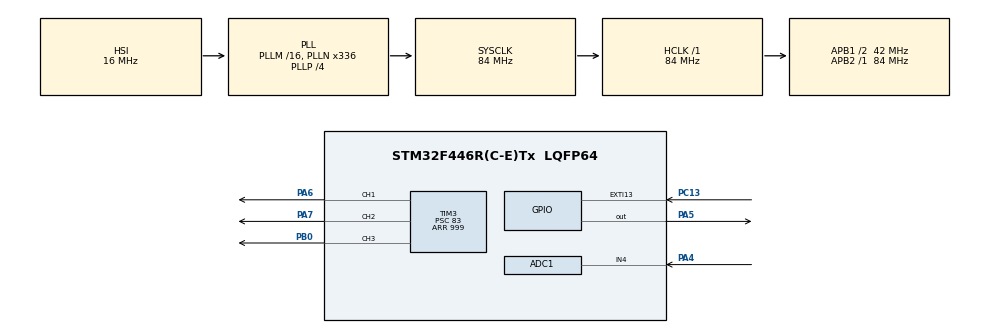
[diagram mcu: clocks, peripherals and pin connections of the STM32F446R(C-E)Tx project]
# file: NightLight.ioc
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ADC1.Channel-0\#ChannelRegularConversion=ADC_CHANNEL_4
ADC1.ExternalTrigConv=ADC_EXTERNALTRIGCONV_T2_TRGO
ADC1.NbrOfConversion=1
ADC1.NbrOfConversionFlag=1
ADC1.Rank-0\#ChannelRegularConversion=1
ADC1.SamplingTime-0\#ChannelRegularConversion=ADC_SAMPLETIME_84CYCLES
ADC1.master=1
Mcu.Family=STM32F4
Mcu.Name=STM32F446R(C-E)Tx
Mcu.Package=LQFP64
NUCLEO-F446RE.BUTTON=1
NUCLEO-F446RE.LD1=true
NVIC.ADC_IRQn=true\:0\:0\:false\:false\:true\:true\:true\:true
NVIC.EXTI15_10_IRQn=true\:0\:0\:false\:false\:true\:false\:true\:true
NVIC.PriorityGroup=NVIC_PRIORITYGROUP_0
PA13.GPIO_Label=TMS
PA13.Signal=SYS_JTMS-SWDIO
PA14.GPIO_Label=TCK
PA14.Signal=SYS_JTCK-SWCLK
PA2.GPIO_Label=USART_TX
PA2.Signal=USART2_TX
PA3.GPIO_Label=USART_RX
PA3.Signal=USART2_RX
PA4.Signal=SharedAnalog_PA4
PA5.Signal=GPIO_Output
PA6.Signal=S_TIM3_CH1
PA7.Signal=S_TIM3_CH2
PB0.Signal=S_TIM3_CH3
PB3.GPIO_Label=SWO
PB3.Signal=SYS_JTDO-SWO
PC13.Signal=GPXTI13
PC14-OSC32_IN.Signal=RCC_OSC32_IN
PC15-OSC32_OUT.Signal=RCC_OSC32_OUT
PH0-OSC_IN.Signal=RCC_OSC_IN
PH1-OSC_OUT.Signal=RCC_OSC_OUT
ProjectManager.HeapSize=0x200
ProjectManager.StackSize=0x400
ProjectManager.TargetToolchain=STM32CubeIDE
RCC.AHBFreq_Value=84000000
RCC.APB1CLKDivider=RCC_HCLK_DIV2
RCC.APB1Freq_Value=42000000
RCC.APB1TimFreq_Value=84000000
RCC.APB2Freq_Value=84000000
RCC.APB2TimFreq_Value=84000000
RCC.CortexFreq_Value=84000000
RCC.FLatency-AdvancedSettings=FLASH_LATENCY_2
RCC.HCLKFreq_Value=84000000
RCC.HSE_VALUE=8000000
RCC.HSI_VALUE=16000000
RCC.LSE_VALUE=32768
RCC.PLLN=336
RCC.PLLP=RCC_PLLP_DIV4
RCC.SYSCLKFreq_VALUE=84000000
RCC.SYSCLKSource=RCC_SYSCLKSOURCE_PLLCLK
RCC.USBFreq_Value=168000000
RCC.VCOOutputFreq_Value=336000000
SH.S_TIM3_CH1.0=TIM3_CH1,PWM Generation1 CH1
SH.S_TIM3_CH2.0=TIM3_CH2,PWM Generation2 CH2
SH.S_TIM3_CH3.0=TIM3_CH3,PWM Generation3 CH3
SH.SharedAnalog_PA4.0=ADC1_IN4,IN4
SH.SharedAnalog_PA4.1=DAC_OUT1,DAC_OUT1
TIM2.Period=99
TIM2.Prescaler=8399
TIM2.TIM_MasterOutputTrigger=TIM_TRGO_UPDATE
TIM3.Channel-PWM\ Generation1\ CH1=TIM_CHANNEL_1
TIM3.Channel-PWM\ Generation2\ CH2=TIM_CHANNEL_2
TIM3.Channel-PWM\ Generation3\ CH3=TIM_CHANNEL_3
TIM3.Period=999
TIM3.Prescaler=83
VP_NUCLEO-F446RE_VS_BSP_COMMON.Mode=COMMON
VP_TIM2_VS_ClockSourceINT.Mode=Internal
board=NUCLEO-F446RE

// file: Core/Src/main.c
/* USER CODE BEGIN Header */
/**
  ******************************************************************************
  * @file           : main.c
  * @brief          : Main program body
  ******************************************************************************
  * @attention
  *
  * Copyright (c) 2026 STMicroelectronics.
  * All rights reserved.
  *
  * This software is licensed under terms that can be found in the LICENSE file
  * in the root directory of this software component.
  * If no LICENSE file comes with this software, it is provided AS-IS.
  *
  ******************************************************************************
  */
/* USER CODE END Header */
#include "main.h"

ADC_HandleTypeDef hadc1;

DAC_HandleTypeDef hdac;

TIM_HandleTypeDef htim2;
TIM_HandleTypeDef htim3;

#define ENABLE_DAC_SELFTEST 0 //config, if 1, we disconnect PA4 from the Photoresistor voltage divider

static volatile uint32_t dac_test_value = 0;

#define ADC_MAX  4095U
#define PWM_MAX  999U

/* USER CODE BEGIN PV */
volatile uint32_t debug_adc = 0;
volatile uint32_t debug_brightness = 0;

/* USER CODE END PV */

void SystemClock_Config(void);
static void MX_GPIO_Init(void);
static void MX_ADC1_Init(void);
static void MX_DAC_Init(void);
static void MX_TIM2_Init(void);
static void MX_TIM3_Init(void);

static void update_PWM(uint32_t adc_value)
{
    uint32_t darkness = ADC_MAX - adc_value;

    uint32_t red = 0;
    uint32_t green = 0;
    uint32_t blue = 0;

    if (darkness < 1365U)
    {
        // First third: red ramps
        red = (darkness * PWM_MAX) / 1365U;
    }
    else if (darkness < 2730U)
    {
        // Second third: red on, green ramps
        red = PWM_MAX;
        green = ((darkness - 1365U) * PWM_MAX) / 1365U;

    }
    else
    {
        // Final third: rg on, blue ramps
        red = PWM_MAX;
        green = PWM_MAX;
        blue = ((darkness - 2730U) * PWM_MAX) / 1365U;
	}

    //Scaling to smoother visual transition
    red = red * red / PWM_MAX;
    green = green * green / PWM_MAX;
    blue = blue * blue / (PWM_MAX);

    __HAL_TIM_SET_COMPARE(&htim3, TIM_CHANNEL_1, red);
    __HAL_TIM_SET_COMPARE(&htim3, TIM_CHANNEL_2, green);
    __HAL_TIM_SET_COMPARE(&htim3, TIM_CHANNEL_3, blue);
}

void HAL_ADC_ConvCpltCallback(ADC_HandleTypeDef *hadc)
{
    if (hadc->Instance == ADC1)
    {

        debug_adc = HAL_ADC_GetValue(hadc);

		update_PWM(debug_adc);

		#if ENABLE_DAC_SELFTEST
				dac_test_value += 1;

				if (dac_test_value > 4095)
				{
					dac_test_value = 0;
				}

				HAL_DAC_SetValue(
					&hdac,
					DAC_CHANNEL_1,
					DAC_ALIGN_12B_R,
					dac_test_value
				);
		#endif
    }
}

int main(void)
{
	HAL_Init();
	SystemClock_Config();
	MX_GPIO_Init();
	MX_ADC1_Init();
	MX_DAC_Init();
	MX_TIM2_Init();
	MX_TIM3_Init();

	#if ENABLE_DAC_SELFTEST
		HAL_DAC_Start(&hdac, DAC_CHANNEL_1);
		HAL_DAC_SetValue(&hdac, DAC_CHANNEL_1, DAC_ALIGN_12B_R, dac_test_value);
	#endif

	HAL_TIM_PWM_Start(&htim3, TIM_CHANNEL_1);
	HAL_TIM_PWM_Start(&htim3, TIM_CHANNEL_2);
	HAL_TIM_PWM_Start(&htim3, TIM_CHANNEL_3);

	HAL_ADC_Start_IT(&hadc1);
	HAL_TIM_Base_Start(&htim2);

//  /* Initialize leds */
//  BSP_LED_Init(LED2);
//
//  /* Initialize USER push-button, will be used to trigger an interrupt each time it's pressed.*/
//  BSP_PB_Init(BUTTON_USER, BUTTON_MODE_EXTI);

  /* Infinite loop */
  /* USER CODE BEGIN WHILE */
  while (1)
  {
	  __WFI();
  }
}

void SystemClock_Config(void)
{
  RCC_OscInitTypeDef RCC_OscInitStruct = {0};
  RCC_ClkInitTypeDef RCC_ClkInitStruct = {0};

  /** Configure the main internal regulator output voltage
  */
  __HAL_RCC_PWR_CLK_ENABLE();
  __HAL_PWR_VOLTAGESCALING_CONFIG(PWR_REGULATOR_VOLTAGE_SCALE3);

  /** Initializes the RCC Oscillators according to the specified parameters
  * in the RCC_OscInitTypeDef structure.
  */
  RCC_OscInitStruct.OscillatorType = RCC_OSCILLATORTYPE_HSI;
  RCC_OscInitStruct.HSIState = RCC_HSI_ON;
  RCC_OscInitStruct.HSICalibrationValue = RCC_HSICALIBRATION_DEFAULT;
  RCC_OscInitStruct.PLL.PLLState = RCC_PLL_ON;
  RCC_OscInitStruct.PLL.PLLSource = RCC_PLLSOURCE_HSI;
  RCC_OscInitStruct.PLL.PLLM = 16;
  RCC_OscInitStruct.PLL.PLLN = 336;
  RCC_OscInitStruct.PLL.PLLP = RCC_PLLP_DIV4;
  RCC_OscInitStruct.PLL.PLLQ = 2;
  RCC_OscInitStruct.PLL.PLLR = 2;
  if (HAL_RCC_OscConfig(&RCC_OscInitStruct) != HAL_OK)
  {
    Error_Handler();
  }

  /** Initializes the CPU, AHB and APB buses clocks
  */
  RCC_ClkInitStruct.ClockType = RCC_CLOCKTYPE_HCLK|RCC_CLOCKTYPE_SYSCLK
                              |RCC_CLOCKTYPE_PCLK1|RCC_CLOCKTYPE_PCLK2;
  RCC_ClkInitStruct.SYSCLKSource = RCC_SYSCLKSOURCE_PLLCLK;
  RCC_ClkInitStruct.AHBCLKDivider = RCC_SYSCLK_DIV1;
  RCC_ClkInitStruct.APB1CLKDivider = RCC_HCLK_DIV2;
  RCC_ClkInitStruct.APB2CLKDivider = RCC_HCLK_DIV1;

  if (HAL_RCC_ClockConfig(&RCC_ClkInitStruct, FLASH_LATENCY_2) != HAL_OK)
  {
    Error_Handler();
  }
}

static void MX_ADC1_Init(void)
{

  ADC_ChannelConfTypeDef sConfig = {0};

  /** Configure the global features of the ADC (Clock, Resolution, Data Alignment and number of conversion)
  */
  hadc1.Instance = ADC1;
  hadc1.Init.ClockPrescaler = ADC_CLOCK_SYNC_PCLK_DIV4;
  hadc1.Init.Resolution = ADC_RESOLUTION_12B;
  hadc1.Init.ScanConvMode = DISABLE;
  hadc1.Init.ContinuousConvMode = DISABLE;
  hadc1.Init.DiscontinuousConvMode = DISABLE;
  hadc1.Init.ExternalTrigConvEdge = ADC_EXTERNALTRIGCONVEDGE_RISING;
  hadc1.Init.ExternalTrigConv = ADC_EXTERNALTRIGCONV_T2_TRGO;
  hadc1.Init.DataAlign = ADC_DATAALIGN_RIGHT;
  hadc1.Init.NbrOfConversion = 1;
  hadc1.Init.DMAContinuousRequests = DISABLE;
  hadc1.Init.EOCSelection = ADC_EOC_SINGLE_CONV;
  if (HAL_ADC_Init(&hadc1) != HAL_OK)
  {
    Error_Handler();
  }

  /** Configure for the selected ADC regular channel its corresponding rank in the sequencer and its sample time.
  */
  sConfig.Channel = ADC_CHANNEL_4;
  sConfig.Rank = 1;
  sConfig.SamplingTime = ADC_SAMPLETIME_84CYCLES;
  if (HAL_ADC_ConfigChannel(&hadc1, &sConfig) != HAL_OK)
  {
    Error_Handler();
  }

}

static void MX_DAC_Init(void)
{

  DAC_ChannelConfTypeDef sConfig = {0};

  /** DAC Initialization
  */
  hdac.Instance = DAC;
  if (HAL_DAC_Init(&hdac) != HAL_OK)
  {
    Error_Handler();
  }

  /** DAC channel OUT1 config
  */
  sConfig.DAC_Trigger = DAC_TRIGGER_NONE;
  sConfig.DAC_OutputBuffer = DAC_OUTPUTBUFFER_ENABLE;
  if (HAL_DAC_ConfigChannel(&hdac, &sConfig, DAC_CHANNEL_1) != HAL_OK)
  {
    Error_Handler();
  }

}

static void MX_TIM2_Init(void)
{

  TIM_ClockConfigTypeDef sClockSourceConfig = {0};
  TIM_MasterConfigTypeDef sMasterConfig = {0};

  htim2.Instance = TIM2;
  htim2.Init.Prescaler = 8399;
  htim2.Init.CounterMode = TIM_COUNTERMODE_UP;
  htim2.Init.Period = 99;
  htim2.Init.ClockDivision = TIM_CLOCKDIVISION_DIV1;
  htim2.Init.AutoReloadPreload = TIM_AUTORELOAD_PRELOAD_DISABLE;
  if (HAL_TIM_Base_Init(&htim2) != HAL_OK)
  {
    Error_Handler();
  }
  sClockSourceConfig.ClockSource = TIM_CLOCKSOURCE_INTERNAL;
  if (HAL_TIM_ConfigClockSource(&htim2, &sClockSourceConfig) != HAL_OK)
  {
    Error_Handler();
  }
  sMasterConfig.MasterOutputTrigger = TIM_TRGO_UPDATE;
  sMasterConfig.MasterSlaveMode = TIM_MASTERSLAVEMODE_DISABLE;
  if (HAL_TIMEx_MasterConfigSynchronization(&htim2, &sMasterConfig) != HAL_OK)
  {
    Error_Handler();
  }

}

static void MX_TIM3_Init(void)
{

  TIM_MasterConfigTypeDef sMasterConfig = {0};
  TIM_OC_InitTypeDef sConfigOC = {0};

  htim3.Instance = TIM3;
  htim3.Init.Prescaler = 83;
  htim3.Init.CounterMode = TIM_COUNTERMODE_UP;
  htim3.Init.Period = 999;
  htim3.Init.ClockDivision = TIM_CLOCKDIVISION_DIV1;
  htim3.Init.AutoReloadPreload = TIM_AUTORELOAD_PRELOAD_DISABLE;
  if (HAL_TIM_PWM_Init(&htim3) != HAL_OK)
  {
    Error_Handler();
  }
  sMasterConfig.MasterOutputTrigger = TIM_TRGO_RESET;
  sMasterConfig.MasterSlaveMode = TIM_MASTERSLAVEMODE_DISABLE;
  if (HAL_TIMEx_MasterConfigSynchronization(&htim3, &sMasterConfig) != HAL_OK)
  {
    Error_Handler();
  }
  sConfigOC.OCMode = TIM_OCMODE_PWM1;
  sConfigOC.Pulse = 0;
  sConfigOC.OCPolarity = TIM_OCPOLARITY_HIGH;
  sConfigOC.OCFastMode = TIM_OCFAST_DISABLE;
  if (HAL_TIM_PWM_ConfigChannel(&htim3, &sConfigOC, TIM_CHANNEL_1) != HAL_OK)
  {
    Error_Handler();
  }
  if (HAL_TIM_PWM_ConfigChannel(&htim3, &sConfigOC, TIM_CHANNEL_2) != HAL_OK)
  {
    Error_Handler();
  }
  if (HAL_TIM_PWM_ConfigChannel(&htim3, &sConfigOC, TIM_CHANNEL_3) != HAL_OK)
  {
    Error_Handler();
  }
  HAL_TIM_MspPostInit(&htim3);

}

static void MX_GPIO_Init(void)
{
  GPIO_InitTypeDef GPIO_InitStruct = {0};

  /* GPIO Ports Clock Enable */
  __HAL_RCC_GPIOC_CLK_ENABLE();
  __HAL_RCC_GPIOH_CLK_ENABLE();
  __HAL_RCC_GPIOA_CLK_ENABLE();
  __HAL_RCC_GPIOB_CLK_ENABLE();

  /*Configure GPIO pins : USART_TX_Pin USART_RX_Pin */
  GPIO_InitStruct.Pin = USART_TX_Pin|USART_RX_Pin;
  GPIO_InitStruct.Mode = GPIO_MODE_AF_PP;
  GPIO_InitStruct.Pull = GPIO_NOPULL;
  GPIO_InitStruct.Speed = GPIO_SPEED_FREQ_VERY_HIGH;
  GPIO_InitStruct.Alternate = GPIO_AF7_USART2;
  HAL_GPIO_Init(GPIOA, &GPIO_InitStruct);

}

void Error_Handler(void)
{
  __disable_irq();
  while (1)
  {
  }
}
